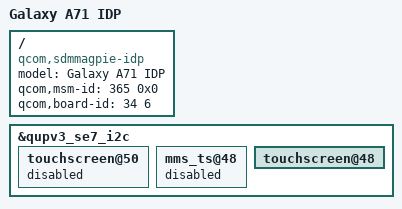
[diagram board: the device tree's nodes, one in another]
/dts-v1/;
/plugin/;

#include <dt-bindings/interrupt-controller/arm-gic.h>
#include <dt-bindings/clock/qcom,camcc-sdmmagpie.h>

#include "sdmmagpie-idp.dtsi"
#include "sdmmagpie-audio-overlay.dtsi"

#include "samsung/a71n.dtsi"
/ {
	model = "Galaxy A71 IDP";
	compatible = "qcom,sdmmagpie-idp", "qcom,sdmmagpie", "qcom,idp";
	qcom,msm-id = <365 0x0>; 
	qcom,board-id = <34 6>; 
}; 
 
&qupv3_se7_i2c { 
	touchscreen@50 {
		status = "disabled";
	}; 
	mms_ts@48 {
		status = "disabled";
	};
	touchscreen@48 {
		status = "ok";
	};
};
